# A64 register map
Vendor: Allwinner; Series: A64; File version: 0.1
CPU: CA53 0, little endian, MPU, no FPU, 0 interrupt priority bits
Registers are 32-bit, read-write, reset 0x0 unless marked. A register's access mark holds for its fields unless they carry their own. Offsets are from the block's base; [hi:lo] are bit positions; {n}, {i} and the like mark numbered series; 'fields as' and 'values as' point back to an identical list.

## CCU (part 2 of 2)
Base 0x01C20000
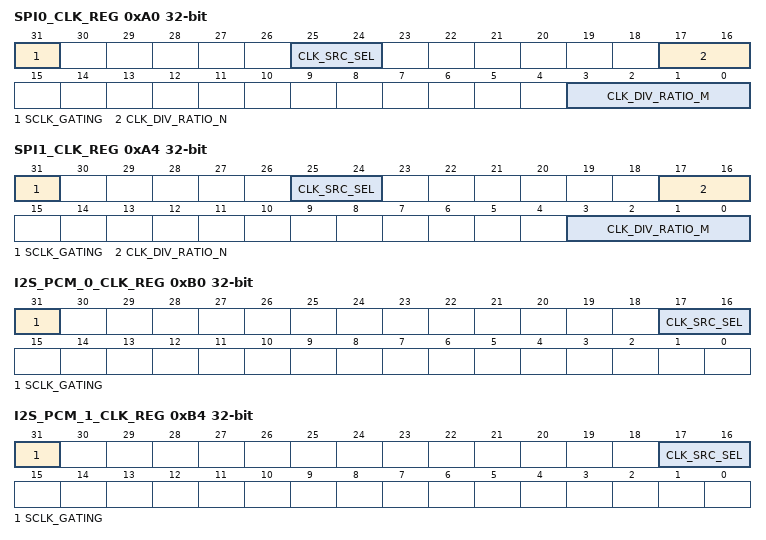
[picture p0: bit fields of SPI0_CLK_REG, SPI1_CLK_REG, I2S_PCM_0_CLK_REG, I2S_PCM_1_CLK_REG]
0xA0 SPI0_CLK_REG — SPI0 Clock Register
  [31] SCLK_GATING — Gating Special Clock(Max Clock = 200MHz) 0: Clock is OFF 1: Clock is ON. SCLK = Clock Source/Divider N/Divider M.
    0=OFF (Clock is OFF); 1=ON (Clock is ON. SCLK = Clock Source/Divider N/Divider M.)
  [25:24] CLK_SRC_SEL — Clock Source Select 00: OSC24M 01: PLL_PERIPH0(1X) 10: PLL_PERIPH1(1X) 11: /
    0=OSC24M; 1=PLL_PERIPH0_openingparen_1X_closingparen_ (PLL_PERIPH0(1X)); 2=PLL_PERIPH1_openingparen_1X_closingparen_ (PLL_PERIPH1(1X))
  [17:16] CLK_DIV_RATIO_N — Clock Pre Divide Ratio (n) 00: /1 01: /2 10: /4 11: /8.
    0=_slash_1 (/1); 1=_slash_2 (/2); 2=_slash_4 (/4); 3=_slash_8 (/8.)
  [3:0] CLK_DIV_RATIO_M — Clock Divide Ratio (m) The pre-divided clock is divided by (m+1). The divider M is from 1 to 16.
0xA4 SPI1_CLK_REG — SPI1 Clock Register
  [31] SCLK_GATING — Gating Special Clock(Max Clock = 200MHz) 0: Clock is OFF 1: Clock is ON. SCLK= Clock Source/Divider N/Divider M.
    0=OFF (Clock is OFF); 1=ON (Clock is ON. SCLK= Clock Source/Divider N/Divider M.)
  [25:24] CLK_SRC_SEL — Clock Source Select 00: OSC24M 01: PLL_PERIPH0(1X) 10: PLL_PERIPH1(1X) 11: /
    values as SPI0_CLK_REG.CLK_SRC_SEL
  [17:16] CLK_DIV_RATIO_N — Clock Pre Divide Ratio (n) 00: /1 01: /2 10: /4 11: /8.
    values as SPI0_CLK_REG.CLK_DIV_RATIO_N
  [3:0] CLK_DIV_RATIO_M — Clock Divide Ratio (m) The pre-divided clock is divided by (m+1). The divider M is from 1 to 16.
0xB0 I2S_PCM_0_CLK_REG
  [31] SCLK_GATING — Gating Special Clock(Max Clock = 200MHz) 0: Clock is OFF 1: Clock is ON.
    0=OFF (Clock is OFF); 1=ON (Clock is ON.)
  [17:16] CLK_SRC_SEL — 00: PLL_AUDIO(8X) 01: PLL_AUDIO(8X)/2 10: PLL_AUDIO(8X)/4 11: PLL_AUDIO
    0=PLL_AUDIO_openingparen_8X_closingparen_ (PLL_AUDIO(8X)); 1=PLL_AUDIO_openingparen_8X_closingparen__slash_2 (PLL_AUDIO(8X)/2); 2=PLL_AUDIO_openingparen_8X_closingparen__slash_4 (PLL_AUDIO(8X)/4); 3=PLL_AUDIO
0xB4 I2S_PCM_1_CLK_REG
  [31] SCLK_GATING — Gating Special Clock(Max Clock = 200MHz) 0: Clock is OFF 1: Clock is ON.
    0=OFF (Clock is OFF); 1=ON (Clock is ON.)
  [17:16] CLK_SRC_SEL — 00: PLL_AUDIO (8X) 01: PLL_AUDIO(8X)/2 10: PLL_AUDIO(8X)/4 11: PLL_AUDIO
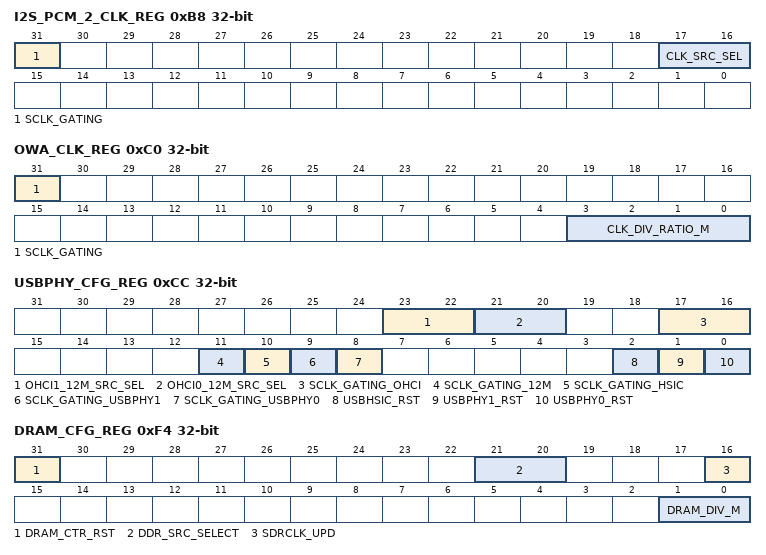
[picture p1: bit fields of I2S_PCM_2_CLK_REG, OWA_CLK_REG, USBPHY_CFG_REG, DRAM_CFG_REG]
0xB8 I2S_PCM_2_CLK_REG
  fields as I2S_PCM_0_CLK_REG
0xC0 OWA_CLK_REG
  [31] SCLK_GATING — Gating Special Clock(Max Clock = 200MHz) 0: Clock is OFF 1: Clock is ON. SCLK= PLL_AUDIO/Divider M.
    0=OFF (Clock is OFF); 1=ON (Clock is ON. SCLK= PLL_AUDIO/Divider M.)
  [3:0] CLK_DIV_RATIO_M — Clock Divide Ratio (m) The pre-divided clock is divided by (m+1). The divider M is from 1 to 16.
0xCC USBPHY_CFG_REG — USBPHY Configuration Register
  [23:22] OHCI1_12M_SRC_SEL — OHCI1 12M Source Select 00: 12M divided from 48M 01: 12M divided from 24M 10: LOSC 11: /
  [21:20] OHCI0_12M_SRC_SEL — OHCI0 12M Source Select 00: 12M divided from 48M 01: 12M divided from 24M 10: LOSC 11: /
  [17:16] SCLK_GATING_OHCI — Gating Special Clock For OHCI(48M and 12M) 00: Clock is OFF 01: OTG-OHCI Clock is ON 10: Clock is OFF 11:OTG-OHCI and OHCI0 Clock is ON
  [11] SCLK_GATING_12M — Gating Special 12M Clock For HSIC 0: Clock is OFF 1: Clock is ON. The special 12M clock = OSC24M/2.
    0=OFF (Clock is OFF); 1=ON (Clock is ON. The special 12M clock = OSC24M/2.)
  [10] SCLK_GATING_HSIC — Gating Special Clock For HSIC 0: Clock is OFF 1: Clock is ON. The special clock is from PLL_HSIC.
    0=OFF (Clock is OFF); 1=ON (Clock is ON. The special clock is from PLL_HSIC.)
  [9] SCLK_GATING_USBPHY1 — Gating Special Clock For USB PHY1 0: Clock is OFF 1: Clock is ON
    0=OFF (Clock is OFF); 1=ON (Clock is ON)
  [8] SCLK_GATING_USBPHY0 — Gating Special Clock For USB PHY0 0: Clock is OFF 1: Clock is ON
    0=OFF (Clock is OFF); 1=ON (Clock is ON)
  [2] USBHSIC_RST — USB HSIC Reset Control 0: Assert 1: De-assert.
    0=Assert; 1=deassert
  [1] USBPHY1_RST — USB PHY1 Reset Control 0: Assert 1: De-assert
    0=Assert; 1=deassert
  [0] USBPHY0_RST — USB PHY0 Reset Control 0: Assert 1: De-assert
    0=Assert; 1=deassert
0xF4 DRAM_CFG_REG — DRAM Configuration Register
  [31] DRAM_CTR_RST — DRAM Controller Reset For AHB Clock Domain. 0: Assert 1: De-assert.
    0=Assert; 1=deassert
  [21:20] DDR_SRC_SELECT — 00: PLL_DDR0 01: PLL_DDR1 1X: /.
    0=PLL_DDR0; 1=PLL_DDR1; 2=_slash_
  [16] SDRCLK_UPD — SDRCLK Configuration Update. 0:Invalid 1:Valid. Note: Set this bit will validate Configuration . It will be auto cleared after the Configuration is valid. The DRAMCLK Source is from PLL_DDR.
  [1:0] DRAM_DIV_M — DRAMCLK Divider of Configuration. The clock is divided by (m+1). The divider M should be from 1 to 4.
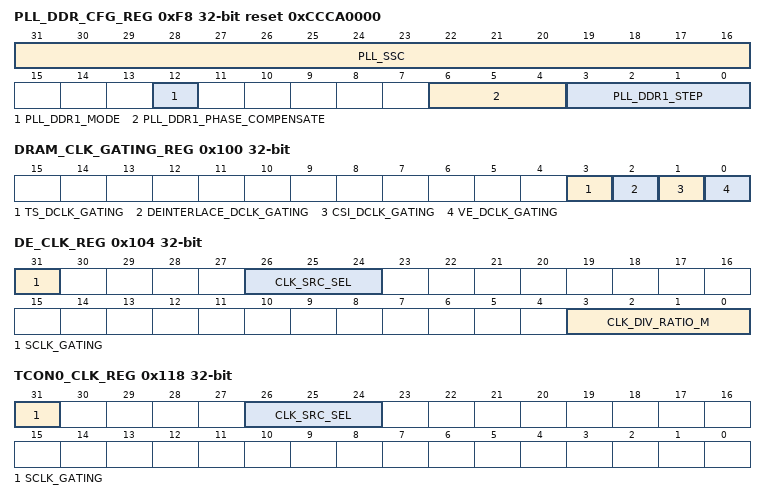
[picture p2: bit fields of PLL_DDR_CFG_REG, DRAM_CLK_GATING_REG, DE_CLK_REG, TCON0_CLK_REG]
0xF8 PLL_DDR_CFG_REG reset 0xCCCA0000 — PLL_DDR Configuration Register
  [31:16] PLL_SSC — The amplitude of SSC must be the integer times of (2^Step). Spread Frequency Amplitude =(SSC Amplitude +2^Step)*24/(2^17),unit is Mhz
  [12] PLL_DDR1_MODE — 0: Normal Mode 1: Continuously Frequency Scale.
    0=Normal Mode; 1=Continuously Frequency Scale
  [6:4] PLL_DDR1_PHASE_COMPENSATE — The value of bit[6:4] is based on 24M clock, then the default PLL_DDR phase compensate is (3/24000000) s.
  [3:0] PLL_DDR1_STEP — 0000: 0.00439MHz/us (576/2^17) 0001: 0.00879MHz/us (576/2^16) 0010: 0.01758MHz/us (576/2^15) 0011: 0.03516MHz/us (576/2^14) 0100: 0.07031MHz/us (576/2^13) 0101: 0.14062MHz/us (576/2^12) 0110: 0.28125MHz/us (576/2^11) 0111: 0.56250MHz/us (576/2^10) 1000: 1.12500MHz/us (576/2^9) 1001: 2.25000MHz/us (576/2^8) 1010: 4.50000Mhz/us (576/2^7) 1011: 9.00000Mhz/us (576/2^6) Others: 0.00439MHz/us (576/2^17).
    0=_0_point_00439MHz_slash_us (0.00439MHz/us (576/2^17)); 1=_0_point_00879MHz_slash_us (0.00879MHz/us (576/2^16)); 2=_0_point_01758MHz_slash_us (0.01758MHz/us (576/2^15)); 3=_0_point_03516MHz_slash_us (0.03516MHz/us (576/2^14)); 4=_0_point_07031MHz_slash_us (0.07031MHz/us (576/2^13)); 5=_0_point_14062MHz_slash_us (0.14062MHz/us (576/2^12)); 6=_0_point_28125MHz_slash_us (0.28125MHz/us (576/2^11)); 7=_0_point_56250MHz_slash_us (0.56250MHz/us (576/2^10)); 8=_1_point_12500MHz_slash_us (1.12500MHz/us (576/2^9)); 9=_2_point_25000MHz_slash_us (2.25000MHz/us (576/2^8)); 10=_4_point_50000Mhz_slash_us (4.50000Mhz/us (576/2^7)); 11=_9_point_00000Mhz_slash_us (9.00000Mhz/us (576/2^6) Others: 0.00439MHz/us (576/2^17).)
0xFC MBUS_RST_REG reset 0x80000000 — MBUS Reset Register
  [31] MBUS_RESET — 0: Assert 1: De-assert.
    0=Assert; 1=deassert
0x100 DRAM_CLK_GATING_REG — DRAM Clock Gating Register
  [all] fields
    0=Mask; 1=Pass
  [3] TS_DCLK_GATING — Gating DRAM Clock For TS 0: Mask 1: Pass
  [2] DEINTERLACE_DCLK_GATING — Gating DRAM SCLK(1X) For DEINTERLACE 0: Mask 1: Pass
  [1] CSI_DCLK_GATING — Gating DRAM Clock For CSI 0: Mask 1: Pass
  [0] VE_DCLK_GATING — Gating DRAM Clock For VE 0: Mask 1: Pass
0x104 DE_CLK_REG — DE Clock Register
  [31] SCLK_GATING — Gating Special Clock 0: Clock is OFF 1: Clock is ON This special clock = Clock Source/Divider M.
    0=OFF (Clock is OFF); 1=ON (Clock is ON This special clock = Clock Source/Divider M.)
  [26:24] CLK_SRC_SEL — Clock Source Select 000: PLL_PERIPH0(2X) 001: PLL_DE Others: /
    0=PLL_PERIPH0_openingparen_2X_closingparen_ (PLL_PERIPH0(2X)); 1=PLL_DE (PLL_DE Others: /)
  [3:0] CLK_DIV_RATIO_M — Clock Divide Ratio (m) The pre-divided clock is divided by (m+1). The divider is from 1 to 16.
0x118 TCON0_CLK_REG — TCON0 Clock Register
  [31] SCLK_GATING — Gating Special Clock 0: Clock is OFF 1: Clock is ON.
    0=OFF (Clock is OFF); 1=ON (Clock is ON.)
  [26:24] CLK_SRC_SEL — Clock Source Select 000: PLL_MIPI 001: / 010: PLL_VIDEO0(2X) 011~111: /.
    0=PLL_MIPI; 2=PLL_VIDEO0_openingparen_2X_closingparen_ (PLL_VIDEO0(2X) 011~111: /.)
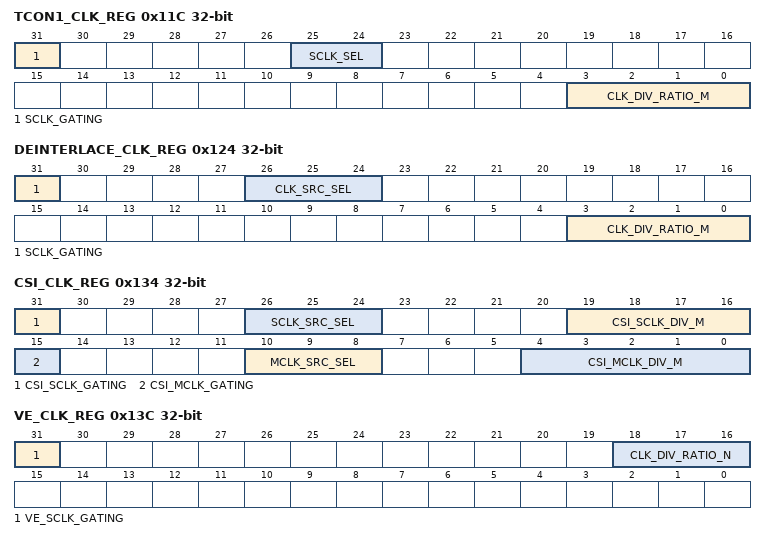
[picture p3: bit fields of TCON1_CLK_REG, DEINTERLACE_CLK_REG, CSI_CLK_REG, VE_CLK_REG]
0x11C TCON1_CLK_REG — TCON1 Clock Register
  [31] SCLK_GATING — Gating Special Clock 0: Clock is OFF 1: Clock is ON. SCLK = Clock Source/ Divider M.
    0=OFF (Clock is OFF); 1=ON (Clock is ON. SCLK = Clock Source/ Divider M.)
  [25:24] SCLK_SEL — Special Clock Source Select 00: PLL_VIDEO0(1X) 01: / 10: PLL_VIDEO1(1X) 11: /.
    0=PLL_VIDEO0_openingparen_1X_closingparen_ (PLL_VIDEO0(1X)); 2=PLL_VIDEO1_openingparen_1X_closingparen_ (PLL_VIDEO1(1X)); 3=_slash_
  [3:0] CLK_DIV_RATIO_M — Clock divide ratio (m) The pre-divided clock is divided by (m+1). The divider is from 1 to 16.
0x124 DEINTERLACE_CLK_REG — DEINTERLACE Clock Register
  [31] SCLK_GATING — Gating Special Clock 0: Clock is OFF 1: Clock is ON SCLK = Clock Source/ Divider M
    0=OFF (Clock is OFF); 1=ON (Clock is ON SCLK = Clock Source/ Divider M)
  [26:24] CLK_SRC_SEL — Clock Source Select 000: PLL_PERIPH0(1X) 001: PLL_PERIPH1(1X) Others: /
    0=PLL_PERIPH0_openingparen_1X_closingparen_ (PLL_PERIPH0(1X)); 1=PLL_PERIPH1_openingparen_1X_closingparen_ (PLL_PERIPH1(1X) Others: /)
  [3:0] CLK_DIV_RATIO_M — Clock Divide Ratio (m) The pre-divided clock is divided by (m+1). The divider is from 1 to 16.
0x130 CSI_MISC_CLK_REG — CSI_MISC Clock Register
  [31] CSI_MISC_SCLK_GATING — Gating Special Clock 0: Clock is OFF 1: Clock is ON SCLK = OSC24M.
    0=OFF (Clock is OFF); 1=ON (Clock is ON SCLK = OSC24M.)
0x134 CSI_CLK_REG — CSI Clock Register
  [31] CSI_SCLK_GATING — Gating Special Clock 0: Clock is OFF 1: Clock is ON. SCLK= Special Clock Source/CSI_SCLK_DIV_M.
    0=OFF (Clock is OFF); 1=ON (Clock is ON. SCLK= Special Clock Source/CSI_SCLK_DIV_M.)
  [26:24] SCLK_SRC_SEL — Special Clock Source Select 000: PLL_PERIPH0(1X) 001: PLL_PERIPH1(1X) Others: /
    values as DEINTERLACE_CLK_REG.CLK_SRC_SEL
  [19:16] CSI_SCLK_DIV_M — CSI Clock Divide Ratio (m) The pre-divided clock is divided by (m+1). The divider M is from 1 to 16.
  [15] CSI_MCLK_GATING — Gating Master Clock 0: Clock is OFF 1: Clock is ON This clock =Master Clock Source/ CSI_MCLK_DIV_M.
    0=OFF (Clock is OFF); 1=ON (Clock is ON This clock =Master Clock Source/ CSI_MCLK_DIV_M.)
  [10:8] MCLK_SRC_SEL — Master Clock Source Select 000: OSC24M 001: PLL_VIDEO1(1X) 010: PLL_PERIPH1 Others: /
    0=OSC24M; 1=PLL_VIDEO1_openingparen_1X_closingparen_ (PLL_VIDEO1(1X)); 2=PLL_PERIPH1 (PLL_PERIPH1 Others: /)
  [4:0] CSI_MCLK_DIV_M — CSI Master Clock Divide Ratio (m) The pre-divided clock is divided by (m+1). The divider is from 1 to 32.
0x13C VE_CLK_REG — VE Clock Register
  [31] VE_SCLK_GATING — Gating Special Clock 0: Clock is OFF 1: Clock is ON. SCLK = PLL_VE /Divider N.
    0=OFF (Clock is OFF); 1=ON (Clock is ON. SCLK = PLL_VE /Divider N.)
  [18:16] CLK_DIV_RATIO_N — Clock Pre Divide Ratio (N) The select clock source is pre-divided by n+1. The divider N is from 1 to 8.
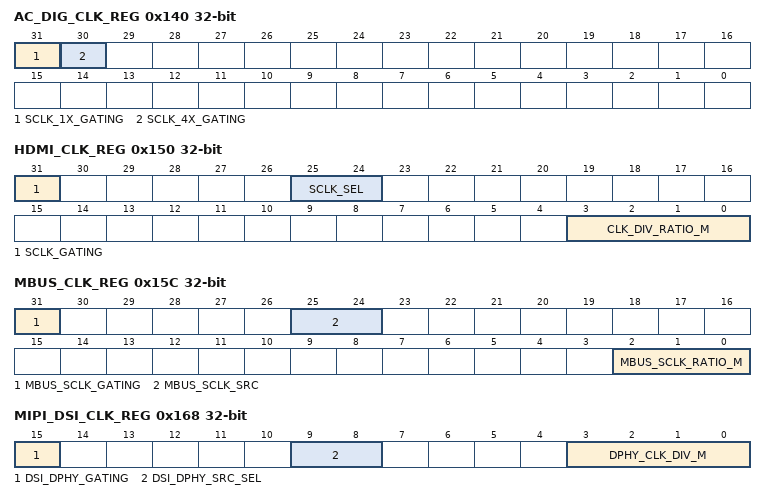
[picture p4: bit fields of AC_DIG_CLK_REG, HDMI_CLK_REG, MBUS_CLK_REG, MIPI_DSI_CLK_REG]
0x140 AC_DIG_CLK_REG — AC Digital Clock Register
  [31] SCLK_1X_GATING — Gating Special Clock 0: Clock is OFF 1: Clock is ON. SCLK = 1X Clock Output.
    0=OFF (Clock is OFF); 1=ON (Clock is ON. SCLK = 1X Clock Output.)
  [30] SCLK_4X_GATING — Gating Special Clock 0: Clock is OFF 1: Clock is ON. SCLK=4X Clock Output.
    0=OFF (Clock is OFF); 1=ON (Clock is ON. SCLK=4X Clock Output.)
0x144 AVS_CLK_REG — AVS Clock Register
  [31] SCLK_GATING — Gating Special Clock 0: Clock is OFF 1: Clock is ON. SCLK= OSC24M.
    0=OFF (Clock is OFF); 1=ON (Clock is ON. SCLK= OSC24M.)
0x150 HDMI_CLK_REG — HDMI Clock Register
  [31] SCLK_GATING — Gating Special Clock 0: Clock is OFF 1: Clock is ON. SCLK= Clock Source/ Divider M.
    0=OFF (Clock is OFF); 1=ON (Clock is ON. SCLK= Clock Source/ Divider M.)
  [25:24] SCLK_SEL — Special Clock Source Select 00: PLL_VIDEO0(1X) 01:PLL_VIDEO1(1X) Others: /
    0=PLL_VIDEO0_openingparen_1X_closingparen_ (PLL_VIDEO0(1X) 01:PLL_VIDEO1(1X) Others: /)
  [3:0] CLK_DIV_RATIO_M — Clock Divide Ratio (m) The pre-divided clock is divided by (m+1). The divider M is from 1 to 16.
0x154 HDMI_SLOW_CLK_REG — HDMI Slow Clock Register
  [31] HDMI_DDC_CLK_GATING — 0: Clock is OFF 1: Clock is ON. SCLK = OSC24M.
    0=OFF (Clock is OFF); 1=ON (Clock is ON. SCLK = OSC24M.)
0x15C MBUS_CLK_REG — MBUS Clock Register
  [31] MBUS_SCLK_GATING — Gating Clock for MBUS 0: Clock is OFF 1: Clock is ON. MBUS_CLOCK = Clock Source/Divider M
    0=OFF (Clock is OFF); 1=ON (Clock is ON. MBUS_CLOCK = Clock Source/Divider M)
  [25:24] MBUS_SCLK_SRC — Clock Source Select 00: OSC24M 01: PLL_PERIPH0(2X) 10: PLL_DDR0 11: PLL_DDR1.
    0=OSC24M; 1=PLL_PERIPH0_openingparen_2X_closingparen_ (PLL_PERIPH0(2X)); 2=PLL_DDR0; 3=PLL_DDR1
  [2:0] MBUS_SCLK_RATIO_M — Clock Divide Ratio (m) The pre-divided clock is divided by (m+1). The divider M is from 1 to 8. Note: If the clock has been changed ,it must wait for at least 16 cycles.
0x168 MIPI_DSI_CLK_REG — MIPI_DSI Clock Register
  [15] DSI_DPHY_GATING — Gating DSI DPHY Clock 0: Clock is OFF 1: Clock is ON. This DSI DPHY clock =Clock Source/ DPHY_CLK_DIV_M.
    0=OFF (Clock is OFF); 1=ON (Clock is ON. This DSI DPHY clock =Clock Source/ DPHY_CLK_DIV_M.)
  [9:8] DSI_DPHY_SRC_SEL — DSI DPHY Clock Source Select. 00: PLL_VIDEO0(1X) 01: / 10: PLL_PERIPH0(1X) 11: /.
    0=PLL_VIDEO0_openingparen_1X_closingparen_ (PLL_VIDEO0(1X)); 2=PLL_PERIPH0_openingparen_1X_closingparen_ (PLL_PERIPH0(1X)); 3=_slash_
  [3:0] DPHY_CLK_DIV_M — DSI DPHY Clock divide ratio (m) The pre-divided clock is divided by (m+1). The divider is from 1 to 16.
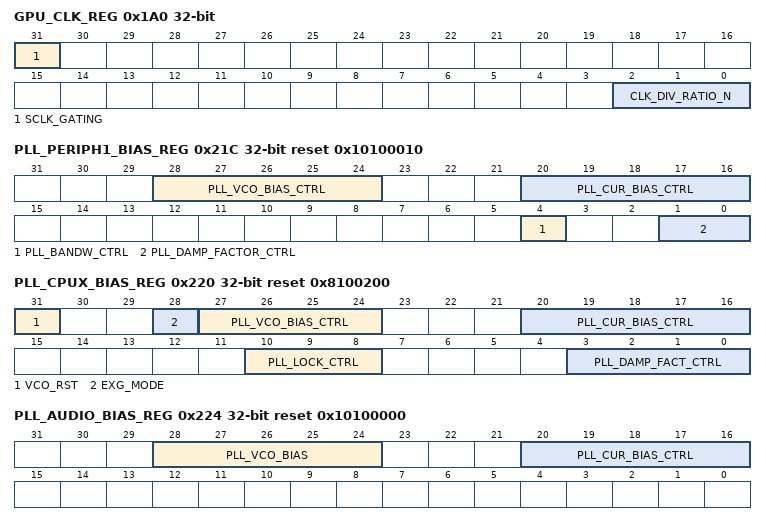
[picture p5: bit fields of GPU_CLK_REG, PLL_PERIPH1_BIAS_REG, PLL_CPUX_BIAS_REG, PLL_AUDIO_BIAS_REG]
0x1A0 GPU_CLK_REG — GPU Clock Register
  [31] SCLK_GATING — 0: Clock is OFF 1: Clock is ON. SCLK= PLL_GPU/Divider N.
    0=OFF (Clock is OFF); 1=ON (Clock is ON. SCLK= PLL_GPU/Divider N.)
  [2:0] CLK_DIV_RATIO_N — Clock Pre Divide Ratio (N) The select clock source is pre-divided by( n+1). The divider N is from 1 to 8.
0x200 PLL_STABLE_TIME_REG0 reset 0xFF — PLL Stable Time Register0
  [15:0] PLL_LOCK_TIME — PLL Lock Time (Unit: us). Note: When any PLL (except PLL_CPU) is enabled or changed, the corresponding PLL lock bit will be set after the PLL STABLE Time.
0x204 PLL_STABLE_TIME_REG1 reset 0xFF — PLL Stable Time Register1
  [15:0] PLL_CPU_LOCK_TIME — PLL_CPU Lock Time (Unit: us). Note: When PLL_CPU is enabled or changed, the PLL_CPU lock bit will be set after the PLL_CPU STABLE Time.
0x21C PLL_PERIPH1_BIAS_REG reset 0x10100010 — PLL_PERIPH1 Bias Register
  [28:24] PLL_VCO_BIAS_CTRL — PLL VCO Bias Control[4:0].
  [20:16] PLL_CUR_BIAS_CTRL — PLL Current Bias Control[4:0].
  [4] PLL_BANDW_CTRL — PLL Band Width Control. 0: Narrow 1: Wide.
    0=Narrow; 1=Wide
  [1:0] PLL_DAMP_FACTOR_CTRL — PLL Damping Factor Control[1:0].
0x220 PLL_CPUX_BIAS_REG reset 0x8100200 — PLL_CPUX Bias Register
  [31] VCO_RST — VCO reset in.
  [28] EXG_MODE — Exchange Mode. Note: CPU PLL source will select PLL_PERIPH0 instead of PLL_CPU
  [27:24] PLL_VCO_BIAS_CTRL — PLL VCO Bias Control[3:0].
  [20:16] PLL_CUR_BIAS_CTRL — PLL Current Bias Control[4:0].
  [10:8] PLL_LOCK_CTRL — PLL Lock Time Control[2:0].
  [3:0] PLL_DAMP_FACT_CTRL — PLL Damping Factor Control[3:0].
0x224 PLL_AUDIO_BIAS_REG reset 0x10100000 — PLL_AUDIO Bias Register
  [28:24] PLL_VCO_BIAS — PLL VCO Bias Current[4:0].
  [20:16] PLL_CUR_BIAS_CTRL — PLL Current Bias Control[4:0].
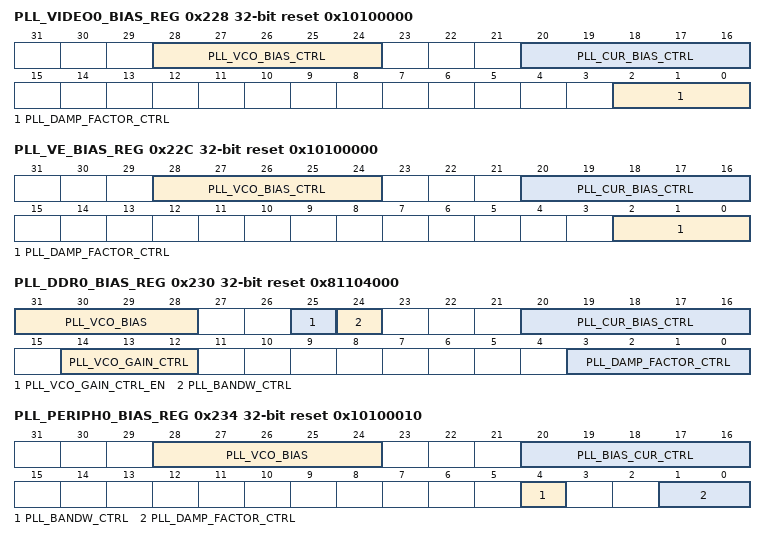
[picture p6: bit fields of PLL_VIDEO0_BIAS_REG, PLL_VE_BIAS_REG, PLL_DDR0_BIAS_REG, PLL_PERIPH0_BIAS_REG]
0x228 PLL_VIDEO0_BIAS_REG reset 0x10100000 — PLL_VIDEO0 Bias Register
  [28:24] PLL_VCO_BIAS_CTRL — PLL VCO Bias Control[4:0].
  [20:16] PLL_CUR_BIAS_CTRL — PLL Current Bias Control[4:0].
  [2:0] PLL_DAMP_FACTOR_CTRL — PLL Damping Factor Control[2:0].
0x22C PLL_VE_BIAS_REG reset 0x10100000 — PLL_VE Bias Register
  fields as PLL_VIDEO0_BIAS_REG
0x230 PLL_DDR0_BIAS_REG reset 0x81104000 — PLL_DDR0 Bias Register
  [31:28] PLL_VCO_BIAS — PLL VCO Bias Control[3:0].
  [25] PLL_VCO_GAIN_CTRL_EN — PLL VCO Gain Control Enable. 0: Disable 1: Enable.
    0=Disable; 1=Enable
  [24] PLL_BANDW_CTRL — PLL Band Width Control. 0: Narrow 1: Wide.
    0=Narrow; 1=Wide
  [20:16] PLL_CUR_BIAS_CTRL — PLL Current Bias Control[4:0].
  [14:12] PLL_VCO_GAIN_CTRL — PLL VCO Gain Control Bit[2:0].
  [3:0] PLL_DAMP_FACTOR_CTRL — PLL Damping Factor Control[3:0].
0x234 PLL_PERIPH0_BIAS_REG reset 0x10100010 — PLL_PERIPH0 Bias Register
  [28:24] PLL_VCO_BIAS — PLL VCO Bias[4:0].
  [20:16] PLL_BIAS_CUR_CTRL — PLL Bias Current Control.
  [4] PLL_BANDW_CTRL — PLL Band Width Control. 0: Narrow 1: Wide
    0=Narrow; 1=Wide
  [1:0] PLL_DAMP_FACTOR_CTRL — PLL Damping Factor Control[1:0].
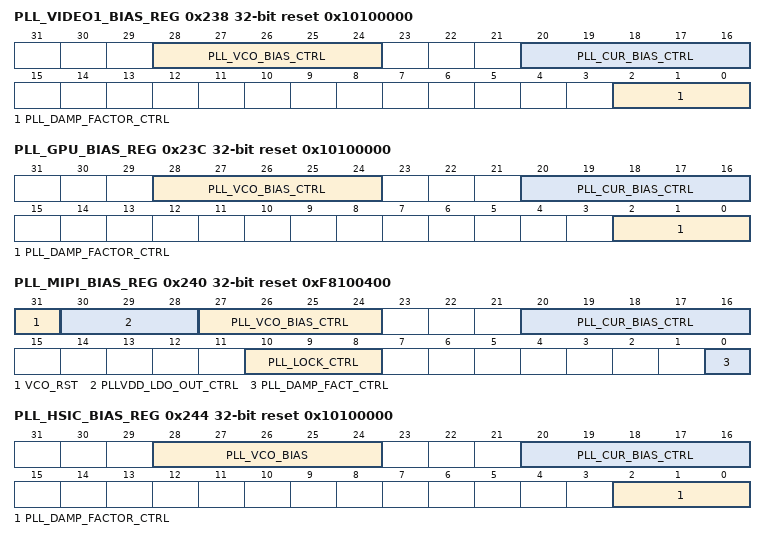
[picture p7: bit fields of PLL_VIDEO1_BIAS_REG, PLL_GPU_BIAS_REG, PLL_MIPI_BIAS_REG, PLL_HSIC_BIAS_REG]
0x238 PLL_VIDEO1_BIAS_REG reset 0x10100000 — PLL_VIDEO1 Bias Register
  fields as PLL_VIDEO0_BIAS_REG
0x23C PLL_GPU_BIAS_REG reset 0x10100000 — PLL_GPU Bias Register
  fields as PLL_VIDEO0_BIAS_REG
0x240 PLL_MIPI_BIAS_REG reset 0xF8100400 — PLL_MIPI Bias Register
  [31] VCO_RST — VCO Reset In.
  [30:28] PLLVDD_LDO_OUT_CTRL — PLLVDD LDO Output Control. PLL_IN_POWER_SEL=1 PLL_IN_POWER_SEL=0 000:1.00v 000:1.20v 001:1.02v 001:1.225v 010:1.04v 010:1.25v 011:1.06v 011:1.275v 100: 1.08v 100:1.30v 101:1.10v 101:1.325v 110:1.12v 110:1.35v 111:1.14v. 111:1.375v The PLL_IN_PWR_SEL is in the PLL_MIPI Tuning Register.
    4=_1_point_08v (1.08v); 4=_1_point_30v (1.30v 101:1.10v 101:1.325v 110:1.12v 110:1.35v 111:1.14v. 111:1.375v The PLL_IN_PWR_SEL is in the PLL_MIPI Tuning Register.)
  [27:24] PLL_VCO_BIAS_CTRL — PLL VCO Bias Control [3:0].
  [20:16] PLL_CUR_BIAS_CTRL — PLL Current Bias Control[4:0].
  [10:8] PLL_LOCK_CTRL — PLL Lock Time Control[2:0].
  [0] PLL_DAMP_FACT_CTRL — PLL Damping Factor Control.
0x244 PLL_HSIC_BIAS_REG reset 0x10100000 — PLL_HSIC Bias Register
  [28:24] PLL_VCO_BIAS — PLL VCO Bias[4:0].
  [20:16] PLL_CUR_BIAS_CTRL — PLL Current Bias Control[4:0].
  [2:0] PLL_DAMP_FACTOR_CTRL — PLL Damping Factor Control[2:0].
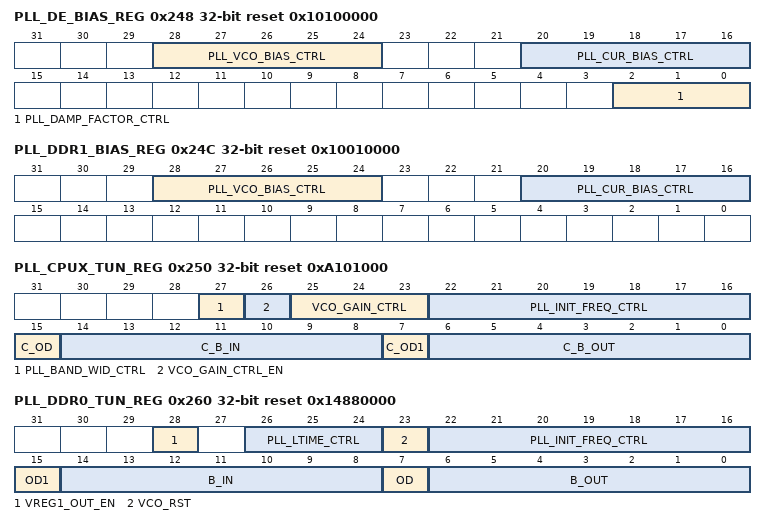
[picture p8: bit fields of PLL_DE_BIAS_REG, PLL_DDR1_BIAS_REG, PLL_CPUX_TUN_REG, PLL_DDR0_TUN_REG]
0x248 PLL_DE_BIAS_REG reset 0x10100000 — PLL_DE Bias Register
  fields as PLL_VIDEO0_BIAS_REG
0x24C PLL_DDR1_BIAS_REG reset 0x10010000 — PLL_DDR1 Bias Register
  [28:24] PLL_VCO_BIAS_CTRL — PLL VCO Bias Control[4:0].
  [20:16] PLL_CUR_BIAS_CTRL — PLL Current Bias Control[4:0].
0x250 PLL_CPUX_TUN_REG reset 0xA101000 — PLL_CPUX Tuning Register
  [27] PLL_BAND_WID_CTRL — PLL Band Width Control. 0: Narrow 1: Wide
    0=Narrow; 1=Wide
  [26] VCO_GAIN_CTRL_EN — VCO Gain Control Enable. 0: Disable 1: Enable
    0=Disable; 1=Enable
  [25:23] VCO_GAIN_CTRL — VCO Gain Control Bits[2:0].
  [22:16] PLL_INIT_FREQ_CTRL — PLL Initial Frequency Control[6:0].
  [15] C_OD — C-Reg-Od For Verify.
  [14:8] C_B_IN — C-B-In[6:0] For Verify.
  [7] C_OD1 — C-Reg-Od1 For Verify.
  [6:0] C_B_OUT ro — C-B-Out[6:0] For Verify.
0x260 PLL_DDR0_TUN_REG reset 0x14880000 — PLL_DDR0 Tuning Register
  [28] VREG1_OUT_EN — Vreg1 Out Enable. 0: Disable 1: Enable
    0=Disable; 1=Enable
  [26:24] PLL_LTIME_CTRL — PLL Lock Time Control[2:0].
  [23] VCO_RST — VCO Reset In.
  [22:16] PLL_INIT_FREQ_CTRL — PLL Initial Frequency Control[6:0].
  [15] OD1 — Reg-Od1 For Verify.
  [14:8] B_IN — B-In[6:0] For Verify.
  [7] OD — Reg-Od For Verify.
  [6:0] B_OUT ro — B-Out[6:0] For Verify.
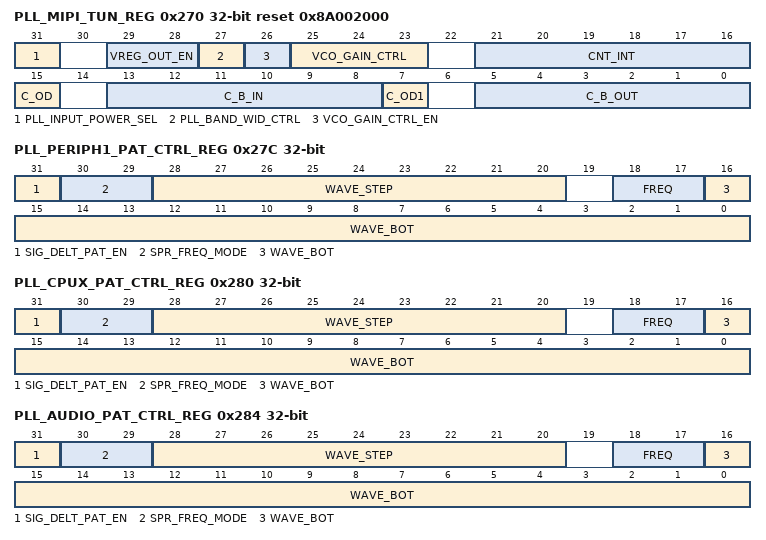
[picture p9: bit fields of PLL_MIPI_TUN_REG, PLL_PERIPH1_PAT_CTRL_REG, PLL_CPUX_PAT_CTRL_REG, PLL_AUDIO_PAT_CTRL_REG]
0x270 PLL_MIPI_TUN_REG reset 0x8A002000 (reset mask 0xBFBFBF80) — PLL_MIPI Tuning Register
  [31] PLL_INPUT_POWER_SEL — 0:2.5V 1:3.0V.
  [29:28] VREG_OUT_EN — For Verify
  [27] PLL_BAND_WID_CTRL — PLL Band Width Control. 0: Narrow 1: Wide.
    0=Narrow; 1=Wide
  [26] VCO_GAIN_CTRL_EN — VCO Gain Control Enable. 0: Disable 1: Enable.
    0=Disable; 1=Enable
  [25:23] VCO_GAIN_CTRL — VCO Gain Control Bits[2:0].
  [21:16] CNT_INT — For Verify[5:0].
  [15] C_OD — C-Reg-Od For Verify
  [13:8] C_B_IN — C-B-In[5:0] For Verify
  [7] C_OD1 — C-Reg-Od1 For Verify
  [5:0] C_B_OUT ro — C-B-Out[5:0] For Verify
0x27C PLL_PERIPH1_PAT_CTRL_REG — PLL_PERIPH1 Pattern Control Register
  [31] SIG_DELT_PAT_EN — Sigma-Delta Pattern Enable.
  [30:29] SPR_FREQ_MODE — Spread Frequency Mode. 00: DC=0 01: DC=1 1X: Triangular.
    0=DC_equals_0 (DC=0); 1=DC_equals_1 (DC=1); 2=Triangular
  [28:20] WAVE_STEP
  [18:17] FREQ — Frequency. 00: 31.5KHz 01: 32KHz 10: 32.5KHz 11: 33KHz.
    0=_31_point_5KHz (31.5KHz); 1=_32KHz; 2=_32_point_5KHz (32.5KHz); 3=_33KHz
  [16:0] WAVE_BOT — Wave Bottom.
0x280 PLL_CPUX_PAT_CTRL_REG — PLL_CPUX Pattern Control Register
  [31] SIG_DELT_PAT_EN — Sigma-delta Pattern Enable.
  [30:29] SPR_FREQ_MODE — Spread Frequency Mode. 00: DC=0 01: DC=1 1X: Triangular
    0=DC_equals_0 (DC=0); 1=DC_equals_1 (DC=1); 2=Triangular
  [28:20] WAVE_STEP
  [18:17] FREQ — Frequency. 00: 31.5KHz 01: 32KHz 10: 32.5KHz 11: 33KHz
    values as PLL_PERIPH1_PAT_CTRL_REG.FREQ
  [16:0] WAVE_BOT — Wave Bottom.
0x284 PLL_AUDIO_PAT_CTRL_REG — PLL_AUDIO Pattern Control Register
  fields as PLL_CPUX_PAT_CTRL_REG
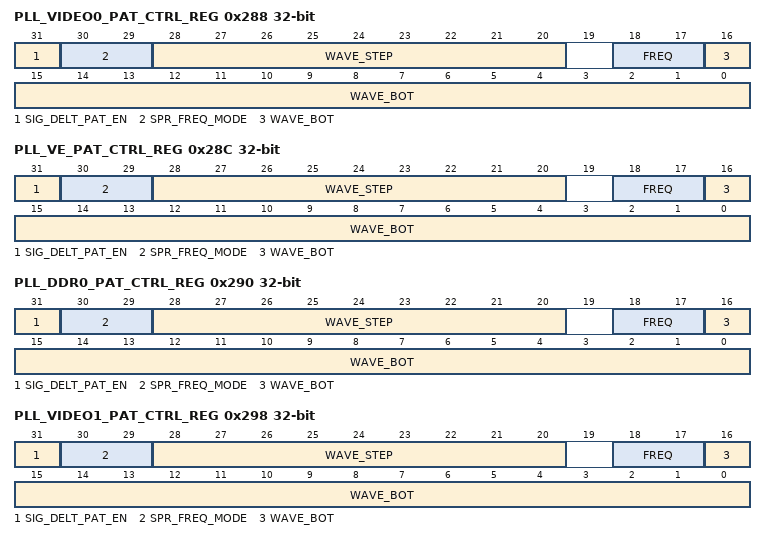
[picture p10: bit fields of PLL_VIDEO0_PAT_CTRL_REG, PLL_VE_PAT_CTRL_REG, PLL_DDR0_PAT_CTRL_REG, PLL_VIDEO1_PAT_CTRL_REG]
0x288 PLL_VIDEO0_PAT_CTRL_REG — PLL_VIDEO0 Pattern Control Register
  fields as PLL_CPUX_PAT_CTRL_REG
0x28C PLL_VE_PAT_CTRL_REG — PLL_VE Pattern Control Register
  fields as PLL_CPUX_PAT_CTRL_REG
0x290 PLL_DDR0_PAT_CTRL_REG — PLL_DDR0 Pattern Control Register
  fields as PLL_CPUX_PAT_CTRL_REG
0x298 PLL_VIDEO1_PAT_CTRL_REG — PLL_VIDEO1 Pattern Control Register
  fields as PLL_PERIPH1_PAT_CTRL_REG
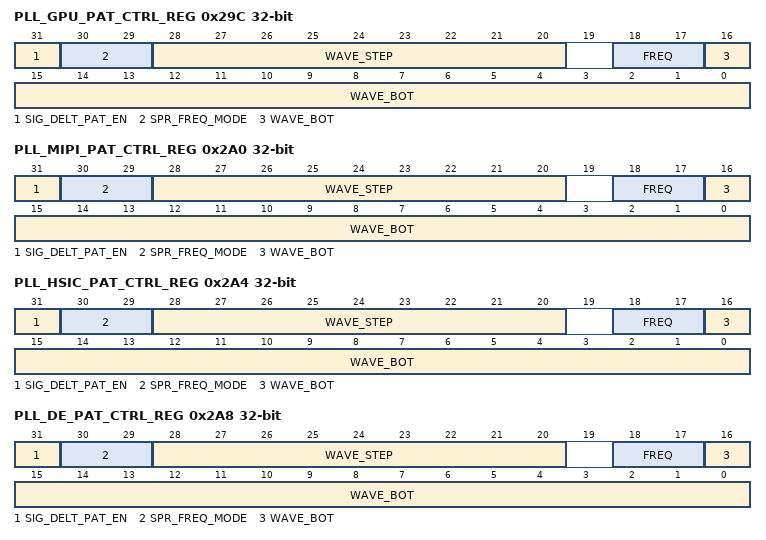
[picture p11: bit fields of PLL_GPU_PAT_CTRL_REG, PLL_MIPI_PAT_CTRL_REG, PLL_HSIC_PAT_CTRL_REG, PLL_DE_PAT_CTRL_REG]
0x29C PLL_GPU_PAT_CTRL_REG — PLL_GPU Pattern Control Register
  [31] SIG_DELT_PAT_EN — Sigma-Delta Pattern Enable.
  [30:29] SPR_FREQ_MODE — Spread Frequency Mode. 00: DC=0 01: DC=1 1X: Triangular
    0=DC_equals_0 (DC=0); 1=DC_equals_1 (DC=1); 2=Triangular
  [28:20] WAVE_STEP
  [18:17] FREQ — Frequency. 00: 31.5KHz 01: 32KHz 10: 32.5KHz 11: 33KHz
    values as PLL_PERIPH1_PAT_CTRL_REG.FREQ
  [16:0] WAVE_BOT — Wave Bottom.
0x2A0 PLL_MIPI_PAT_CTRL_REG — PLL_MIPI Pattern Control Register
  fields as PLL_PERIPH1_PAT_CTRL_REG
0x2A4 PLL_HSIC_PAT_CTRL_REG — PLL_HSIC Pattern Control Register
  fields as PLL_GPU_PAT_CTRL_REG
0x2A8 PLL_DE_PAT_CTRL_REG — PLL_DE Pattern Control Register
  fields as PLL_GPU_PAT_CTRL_REG
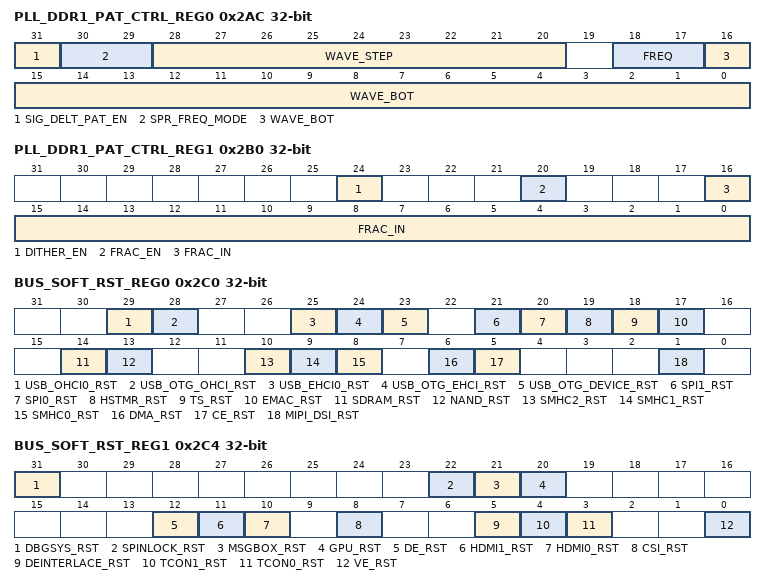
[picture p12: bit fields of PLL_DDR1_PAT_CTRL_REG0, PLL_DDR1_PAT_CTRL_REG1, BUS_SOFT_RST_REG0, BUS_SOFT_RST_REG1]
0x2AC PLL_DDR1_PAT_CTRL_REG0 — PLL_DDR1 Pattern Control Register0
  [31] SIG_DELT_PAT_EN — Sigma-Delta Pattern Enable.
  [30:29] SPR_FREQ_MODE — Spread Frequency Mode. 00: DC=0 01: DC=1 10: / 11: Triangular.
    0=DC_equals_0 (DC=0); 1=DC_equals_1 (DC=1); 3=Triangular
  [28:20] WAVE_STEP
  [18:17] FREQ — Frequency. 00: 31.5KHz 01: 32KHz 10: 32.5KHz 11: 33KHz.
    values as PLL_PERIPH1_PAT_CTRL_REG.FREQ
  [16:0] WAVE_BOT — Wave Bottom.
0x2B0 PLL_DDR1_PAT_CTRL_REG1 — PLL_DDR1 Pattern Control Register1
  [24] DITHER_EN, [20] FRAC_EN, [16:0] FRAC_IN
0x2C0 BUS_SOFT_RST_REG0 — Bus Software Reset Register 0
  [all] fields
    0=Assert; 1=deassert
  [29] USB_OHCI0_RST — USB-OHCI0 Reset Control 0: Assert 1: De-assert
  [28] USB_OTG_OHCI_RST — USB-OTG-OHCI Reset Control 0: Assert 1: De-assert
  [25] USB_EHCI0_RST — USB-EHCI0 Reset Control 0: Assert 1: De-assert.
  [24] USB_OTG_EHCI_RST — USB-OTG-EHCI Reset Control 0: Assert 1: De-assert
  [23] USB_OTG_DEVICE_RST — USB-OTG-Device_RST. USB-OTG-Device Reset Control 0: Assert 1: De-assert
  [21] SPI1_RST — SPI1 Reset. 0: Assert 1: De-assert
  [20] SPI0_RST — SPI0 Reset. 0: Assert 1: De-assert
  [19] HSTMR_RST — HSTMR Reset. 0: Assert 1: De-assert
  [18] TS_RST — TS Reset. 0: Assert 1: De-assert
  [17] EMAC_RST — EMAC Reset. 0: Assert 1: De-assert
  [14] SDRAM_RST — SDRAM AHB Reset. 0: Assert 1: De-assert
  [13] NAND_RST — NAND Reset. 0: Assert 1: De-assert
  [10] SMHC2_RST — SMHC2 Reset. 0: Assert 1: De-assert.
  [9] SMHC1_RST — SMHC1 Reset. 0: Assert 1: De-assert.
  [8] SMHC0_RST — SMHC0 Reset. 0: Assert 1: De-assert.
  [6] DMA_RST — DMA Reset. 0: Assert 1: De-assert
  [5] CE_RST — CE Reset. 0: Assert 1: De-assert
  [1] MIPI_DSI_RST — MIPI DSI Reset. 0: Assert 1: De-assert.
0x2C4 BUS_SOFT_RST_REG1 — Bus Software Reset Register 1
  [31] DBGSYS_RST — DBGSYS Reset. 0: Assert 1: De-assert
    0=Assert; 1=deassert
  [22] SPINLOCK_RST — SPINLOCK Reset. 0: Assert 1: De-assert.
    0=Assert; 1=deassert
  [21] MSGBOX_RST — MSGBOX Reset. 0: Assert 1: De-assert.
    0=Assert; 1=deassert
  [20] GPU_RST — GPU Reset. 0: Assert 1: De-assert.
    0=Assert; 1=deassert
  [12] DE_RST — DE Reset. 0: Assert 1: De-assert.
    0=Assert; 1=deassert
  [11] HDMI1_RST — HDMI1 Reset. 0: Assert 1: De-assert.
    0=Assert; 1=deassert
  [10] HDMI0_RST — HDMI0 Reset. 0: Assert 1: De-assert.
    0=Assert; 1=deassert
  [8] CSI_RST — CSI Reset. 0: Assert 1: De-assert.
    0=Assert; 1=deassert
  [5] DEINTERLACE_RST — DEINTERLACE Reset. 0: Assert 1:De-assert
    0=Assert 1:De-assert
  [4] TCON1_RST — TCON1 Reset. 0: Assert 1: De-assert.
    0=Assert; 1=deassert
  [3] TCON0_RST — TCON0 Reset. 0: Assert 1: De-assert.
    0=Assert; 1=deassert
  [0] VE_RST — VE Reset. 0: Assert 1: De-assert.
    0=Assert; 1=deassert
0x2C8 BUS_SOFT_RST_REG2 — Bus Software Reset Register 2
  [0] LVDS_RST — LVDS Reset. 0: Assert 1: De-assert.
    0=Assert; 1=deassert
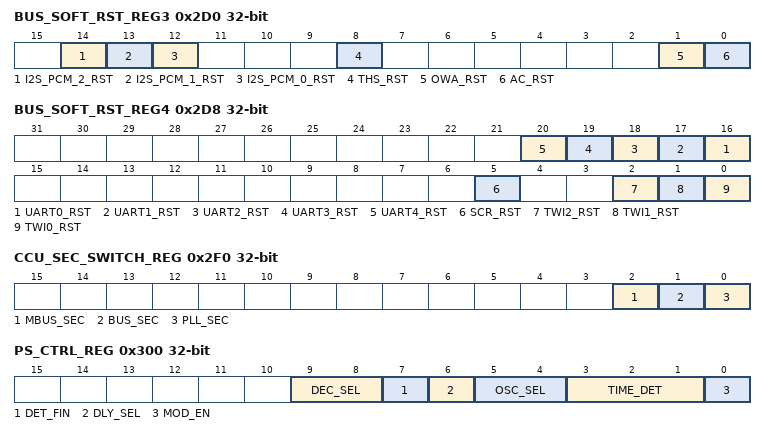
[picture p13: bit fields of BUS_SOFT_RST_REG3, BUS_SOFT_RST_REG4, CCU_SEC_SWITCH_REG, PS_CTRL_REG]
0x2D0 BUS_SOFT_RST_REG3 — Bus Software Reset Register 3
  [all] fields
    0=Assert; 1=deassert
  [14] I2S_PCM_2_RST — I2S_PCM_2 Reset. 0: Assert 1: De-assert.
  [13] I2S_PCM_1_RST — I2S_PCM_1 Reset. 0: Assert 1: De-assert.
  [12] I2S_PCM_0_RST — I2S_PCM_0 Reset. 0: Assert 1: De-assert.
  [8] THS_RST — THS Reset. 0: Assert 1: De-assert
  [1] OWA_RST — OWA Reset. 0: Assert 1: De-assert
  [0] AC_RST — AC Reset. 0: Assert 1: De-assert
0x2D8 BUS_SOFT_RST_REG4 — Bus Software Reset Register 4
  [all] fields
    0=Assert; 1=deassert
  [n+16] UART{n}_RST (n=0..4) — UART{n} Reset. 0: Assert 1: De-assert.
  [5] SCR_RST — SCR Reset. 0: Assert 1: De-assert
  [2] TWI2_RST — TWI2 Reset. 0: Assert 1: De-assert.
  [1] TWI1_RST — TWI1 Reset. 0: Assert 1: De-assert.
  [0] TWI0_RST — TWI0 Reset. 0: Assert 1: De-assert.
0x2F0 CCU_SEC_SWITCH_REG
  [2] MBUS_SEC — MBUS clock register security 0:Secure 1:Non-secure Including MBUS Reset Register and MBUS Clock Register
  [1] BUS_SEC — Bus relevant registers` security 0:Secure 1:Non-secure Including AXI/AHB/APB relevant registers,such as CPUX/AXI Configuration Register,AHB1/APB1 Configuration Register,APB2 Configuration Register, AHB2 Configuration Register.
  [0] PLL_SEC — PLL relevant registers` security. 0:Secure 1:Non-secure Including PLL_CPUX Control Register, PLL_AUDIO Control Register, PLL_VIDEO0 Control Register, PLL_VIDEO1 Control Register, PLL_VE Control Register, PLL_DDR0 Control Register,PLL_DDR1 Control Register, PLL_PERIPH0 Control Register, PLL_PERIPH1 Control Register,PLL_GPU Control Register, PLL_MIPI Control Register, PLL_HSIC Control Register, PLL_DE Control Register and offset from 0x200 to 0x2B0 relevant registers.
0x300 PS_CTRL_REG — PS Control Register
  [9:8] DEC_SEL — Device Select
  [7] DET_FIN — Detect Finish. 0: Unfinished 1: Finished Set 1 to this bit will clear it.
    0=Unfinished; 1=Finished Set 1 to this bit will clear it
  [6] DLY_SEL — Delay Select 0: 1 Cycle 1: 2 Cycles
    0=_1_Cycle; 1=2 Cycles
  [5:4] OSC_SEL — OSC Select. 00: IDLE 01: SVT 10: LVT 11: ULVT
    0=IDLE; 1=SVT; 2=LVT; 3=ULVT
  [3:1] TIME_DET — Time detect. 000: 0.5/4 us 001: 0.5/2 us 002: 0.5/1 us 003: 0.5*2us ........... 111:0.5*2^5us
    0=_0_point_5_slash_4 (0.5/4 us); 1=_0_point_5_slash_2 (0.5/2 us); 2=_0_point_5_slash_1 (0.5/1 us); 3=_0_point_5_times_2us (0.5*2us ........... 111:0.5*2^5us)
  [0] MOD_EN — Module enable. 0: Disable 1: Enable
    0=Disable; 1=Enable
0x304 PS_CNT_REG — PS Counter Register
  [15:0] PS_CNT — PS Counter.
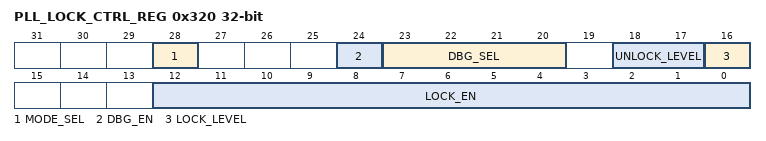
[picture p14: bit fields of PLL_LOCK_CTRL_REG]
0x320 PLL_LOCK_CTRL_REG — PLL Lock Control Register
  [28] MODE_SEL — Mode Select 0: Old Mode 1: New Mode
    0=Old (Old Mode); 1=New (New Mode)
  [24] DBG_EN — Debug Enable 0: Disable 1: Enable
    0=Disable; 1=Enable
  [23:20] DBG_SEL — Debug Select 0000: PLL_CPUX 0001: PLL_AUDIO 0010: PLL_VIDEO0 0011: PLL_VE 0100: PLL_DDR0 0101: PLL_PERIPH0 0110: PLL_VIDEO1 0111: PLL_GPU 1000: PLL_MIPI 1001: PLL_HSIC 1010: PLL_DE 1011: PLL_DDR1 1100: PLL_PERIPH1 Others: /
    0=PLL_CPUX; 1=PLL_AUDIO; 2=PLL_VIDEO0; 3=PLL_VE; 4=PLL_DDR0; 5=PLL_PERIPH0; 6=PLL_VIDEO1; 7=PLL_GPU; 8=PLL_MIPI; 9=PLL_HSIC; 10=PLL_DE; 11=PLL_DDR1; 12=PLL_PERIPH1 (PLL_PERIPH1 Others: /)
  [18:17] UNLOCK_LEVEL — Unlock Level 00: 21-29 Clock Cycles 01: 22-28 Clock Cycles 1X: 20-30 Clock Cycles
    0=_21_minus_29 (21-29 Clock Cycles); 1=_22_minus_28 (22-28 Clock Cycles); 2=_20_minus_30 (20-30 Clock Cycles)
  [16] LOCK_LEVEL — Lock Level 0: 24-26 Clock Cycles 1: 23-27 Clock Cycles
    0=_24_minus_26 (24-26 Clock Cycles); 1=_23_minus_27 (23-27 Clock Cycles)
  [12:0] LOCK_EN — Lock Enable Bit12: PLL_PERIPH1 Bit11: PLL_DDR1 Bit10: PLL_DE Bit9: PLL_HSIC Bit8: PLL_MIPI Bit7: PLL_GPU Bit6: PLL_VIDEO1 Bit5: PLL_PERIPH0 Bit4: PLL_DDR0 Bit3: PLL_VE Bit2: PLL_VIDEO0 Bit1: PLL_AUDIO Bit0: PLL_CPUX
